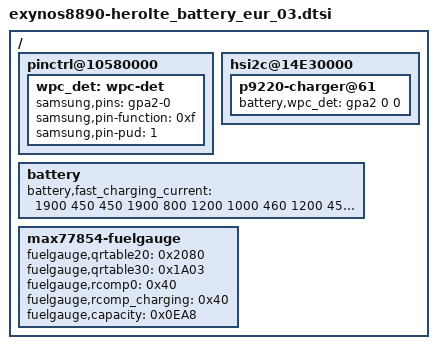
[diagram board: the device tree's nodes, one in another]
/*
 * SAMSUNG UNIVERSAL5433 board device tree source
 *
 * Copyright (c) 2013 Samsung Electronics Co., Ltd.
 *		http://www.samsung.com
 *
 * This program is free software; you can redistribute it and/or modify
 * it under the terms of the GNU General Public License version 2 as
 * published by the Free Software Foundation.
*/

#include "exynos8890-herolte_battery.dtsi"
/ {
	pinctrl@10580000 {
		wpc_det: wpc-det {
			samsung,pins = "gpa2-0";
			samsung,pin-function = <0xf>;
			samsung,pin-pud = <1>;
		};
	};

	hsi2c@14E30000 {
		p9220-charger@61 {
			battery,wpc_det = <&gpa2 0 0>;
		};
	};

	battery {
		battery,fast_charging_current = <1900 450 450 1900 800 1200 1000 460 1200 450 1900 1900 1900 1600 1900 450 450 400 700 1300 300 1000 1500 450 1900 1900 1000 1900 80 1800 1000 1400 450 1000 1900 1900 1900 1900>;
	};

	max77854-fuelgauge {
		fuelgauge,qrtable20 = <0x2080>;
		fuelgauge,qrtable30 = <0x1A03>;
		fuelgauge,rcomp0 = <0x40>;
		fuelgauge,rcomp_charging = <0x40>;
		fuelgauge,capacity = <0x0EA8>;
	};
};
